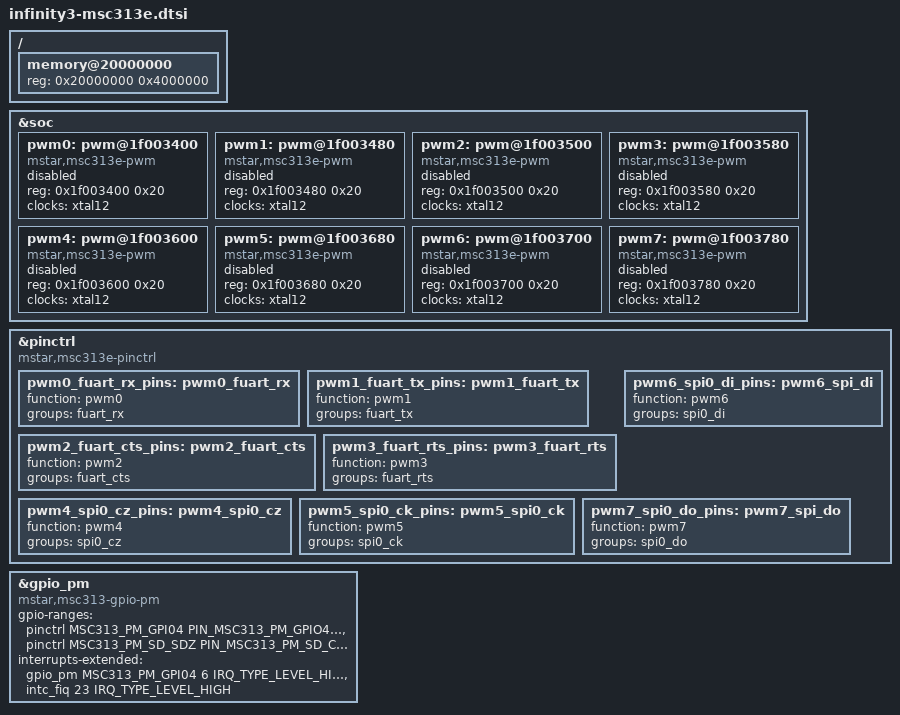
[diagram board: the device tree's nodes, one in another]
// SPDX-License-Identifier: GPL-2.0-or-later
/*
 * Copyright (c) 2020 thingy.jp.
 * Author: Daniel Palmer <daniel@thingy.jp>
 */

#include <dt-bindings/gpio/mstar.h>
#include <dt-bindings/pinctrl/mstar.h>

#include "infinity3.dtsi"

/delete-node/ &pwm0;
/ {
	memory@20000000 {
		device_type = "memory";
		reg = <0x20000000 0x4000000>;
	};
};



&soc {
	pwm0: pwm@1f003400 {
		compatible = "mstar,msc313e-pwm";
		reg = <0x1f003400 0x20>;
		#pwm-cells = <2>;
		clocks = <&xtal12>;
		status = "disabled";
	};

	pwm1: pwm@1f003480 {
		compatible = "mstar,msc313e-pwm";
		reg = <0x1f003480 0x20>;
		#pwm-cells = <2>;
		clocks = <&xtal12>;
		status = "disabled";
	};

	pwm2: pwm@1f003500 {
		compatible = "mstar,msc313e-pwm";
		reg = <0x1f003500 0x20>;
		#pwm-cells = <2>;
		clocks = <&xtal12>;
		status = "disabled";
	};

	pwm3: pwm@1f003580 {
		compatible = "mstar,msc313e-pwm";
		reg = <0x1f003580 0x20>;
		#pwm-cells = <2>;
		clocks = <&xtal12>;
		status = "disabled";
	};

	pwm4: pwm@1f003600 {
		compatible = "mstar,msc313e-pwm";
		reg = <0x1f003600 0x20>;
		#pwm-cells = <2>;
		clocks = <&xtal12>;
		status = "disabled";
	};

	pwm5: pwm@1f003680 {
		compatible = "mstar,msc313e-pwm";
		reg = <0x1f003680 0x20>;
		#pwm-cells = <2>;
		clocks = <&xtal12>;
		status = "disabled";
	};

	pwm6: pwm@1f003700 {
		compatible = "mstar,msc313e-pwm";
		reg = <0x1f003700 0x20>;
		#pwm-cells = <2>;
		clocks = <&xtal12>;
		status = "disabled";
	};

	pwm7: pwm@1f003780 {
		compatible = "mstar,msc313e-pwm";
		reg = <0x1f003780 0x20>;
		#pwm-cells = <2>;
		clocks = <&xtal12>;
		status = "disabled";
	};
	
	/*
	cmdq: cmdq@1 {
		reg = <0 0x200>;
		compatible = "mstar,msc313-cmdq";
		interrupt-parent = <&intc_spi>;
		interrupts = <52 IRQ_TYPE_LEVEL_HIGH>;
		clocks = <&clkgen_mux_mui 0>;
	};*/
	
	/*
	cmdq: cmdq@2 {
		reg = <0 0x200>;
		compatible = "mstar,msc313-cmdq";
		interrupt-parent = <&intc_spi>;
		interrupts = <53 IRQ_TYPE_LEVEL_HIGH>;
		clocks = <&clkgen_mux_mui 0>;
	};*/
};

&pinctrl {
	compatible = "mstar,msc313e-pinctrl";
	pwm0_fuart_rx_pins: pwm0_fuart_rx {
		function = "pwm0";
		groups = "fuart_rx";
	};
	pwm1_fuart_tx_pins: pwm1_fuart_tx {
		function = "pwm1";
		groups = "fuart_tx";
	};
	pwm2_fuart_cts_pins: pwm2_fuart_cts {
		function = "pwm2";
		groups = "fuart_cts";
	};
	pwm3_fuart_rts_pins: pwm3_fuart_rts {
		function = "pwm3";
		groups = "fuart_rts";
	};
	pwm4_spi0_cz_pins: pwm4_spi0_cz {
		function = "pwm4";
		groups = "spi0_cz";
	};
	pwm5_spi0_ck_pins: pwm5_spi0_ck {
		function = "pwm5";
		groups = "spi0_ck";
	};
	pwm6_spi0_di_pins: pwm6_spi_di {
		function = "pwm6";
		groups = "spi0_di";
	};
	pwm7_spi0_do_pins: pwm7_spi_do {
		function = "pwm7";
		groups = "spi0_do";
	};
};

&gpio_pm {
	compatible = "mstar,msc313-gpio-pm";
	gpio-ranges = <&pinctrl MSC313_PM_GPI04 PIN_MSC313_PM_GPIO4 1>,
		      <&pinctrl MSC313_PM_SD_SDZ PIN_MSC313_PM_SD_CDZ 1>;
	interrupts-extended = <&gpio_pm MSC313_PM_GPI04 6 IRQ_TYPE_LEVEL_HIGH>,
			      <&intc_fiq 23 IRQ_TYPE_LEVEL_HIGH>;
	status = "okay";
};
